# STM32MP21_CM33 register map
File version: 0.4
CPU: CM33 r0p1, little endian, MPU, FPU, vendor SysTick, 8 interrupt priority bits
Registers are 32-bit, read-write, reset 0x0 unless marked. A register's access mark holds for its fields unless they carry their own. Offsets are from the block's base; [hi:lo] are bit positions; {n}, {i} and the like mark numbered series; 'fields as' and 'values as' point back to an identical list.

## SERC — SERC register block
Base 0x44080000
Same registers: SERC_S 0x54080000
{0x0+4i} SERC_IER{i} (i=0..5) — SERC interrupt enable register {i}
  [31:0] PDRIE — Power-down or reset interrupt enable for peripheral y
    0=power-down or reset access event from peripheral y does not generate an interrupt (masked); 1=power-down or reset access event from peripheral y generates an interrupt (unmasked)
{0x40+4i} SERC_ISR{i} ro (i=0..4) — SERC interrupt status register {i}
  [31:0] PDRS — Power-down or reset interrupt status for peripheral y
    0=no power-down or reset event recorded for this peripheral; 1=a power-down or reset access event has been reported from this peripheral
0x54 SERC_ISR5 ro — SERC interrupt status register 5
  [31:0] PDRS — Power-down or reset clear flag for peripheral y
    values as SERC_ISR0.PDRS
{0x80+4i} SERC_ICR{i} wo (i=0..5) — SERC interrupt clear register {i}
  [31:0] PDRC — Power-down or reset clear flag for peripheral y
    0=PDRCy flag status is not affected; 1=PDRCy flag status is cleared in SERC_ISR{i} register
0x100 SERC_ENABLE
  [0] SERFEN — Enable the SERF framework.
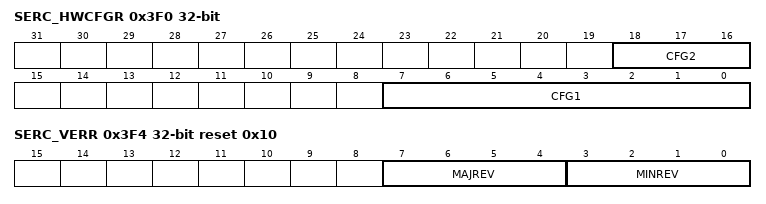
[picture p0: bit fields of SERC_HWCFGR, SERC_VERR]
0x3F0 SERC_HWCFGR ro (reset mask 0xFFF0FF00) — SERC hardware configuration register
  [18:16] CFG2 — NUM_RESYNC_FLOPS, number of resynchronization flops when receiving a bus_ilac information in the SERC clock domain.
  [7:0] CFG1 — NUM_ILAC, number of illegal accesses input pins configured for this instance of the collector.
0x3F4 SERC_VERR ro reset 0x10 — SERC version register
  [7:4] MAJREV — Major revision
  [3:0] MINREV — Minor revision
0x3F8 SERC_IPIDR ro reset 0x1001F0 — SERC identification register
  [31:0] ID — IP identification code
0x3FC SERC_SIDR ro reset 0xA3C5DD01 — SERC size identification register
  [31:0] SID — Size identification code (1 Kbyte)

## STGENC — STGENC address block description
Base 0x48080000
Same registers: STGENC_S 0x58080000
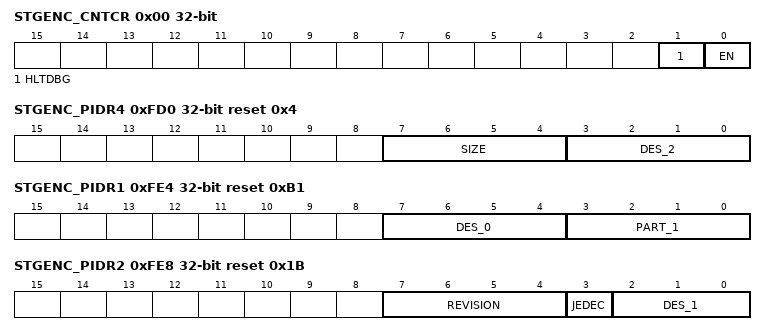
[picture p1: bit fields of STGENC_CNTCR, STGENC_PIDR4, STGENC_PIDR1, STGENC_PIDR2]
0x00 STGENC_CNTCR — STGENC control register
  [1] HLTDBG — Halt on debug
    0=Do not halt on debug; hltdbg signal into the counter has no effect; 1=Halt on debug; when hltdbg is driven high, the count value is held static
  [0] EN — Enable
    0=Counter disabled and not incrementing; 1=Counter enabled and incrementing
0x04 STGENC_CNTSR ro — STGENC status register
  [1] DBGH — Debug halted
    0=Normal operation; 1=Counter halted due to system-wide debug state
0x08 STGENC_CNTCVL — STGENC value lower register
  [31:0] CNTCVL_L_32 — Current value of the timestamp counter, lower 32 bits
0x0C STGENC_CNTCVU — STGENC value upper register
  [31:0] CNTCVU_U_32 — Current value of the timestamp counter, upper 32 bits
0x20 STGENC_CNTFID0 — STGENC base frequency register
  [31:0] FREQ — Frequency in number of ticks per second
0xFD0 STGENC_PIDR4 ro reset 0x4 — STGENC peripheral ID4 register
  [7:4] SIZE — Always 0b0000
  [3:0] DES_2 — Part of designer identification
{0xFC0+4i} STGENC_PIDR{i} ro (i=5..7) — STGENC peripheral ID{i} register
  [31:0] PIDR{i} — Peripheral ID{i}
0xFE0 STGENC_PIDR0 ro reset 0x1 — STGENC peripheral ID0 register
  [7:0] PART_0 — Bits[7:0] of the 12-bit part number of the component
0xFE4 STGENC_PIDR1 ro reset 0xB1 — STGENC peripheral ID1 register
  [7:4] DES_0 — Part of designer identification
  [3:0] PART_1 — Bits[11:8] of the 12-bit part number of the component
0xFE8 STGENC_PIDR2 ro reset 0x1B — STGENC peripheral ID2 register
  [7:4] REVISION — device revision number
  [3] JEDEC — always 1
  [2:0] DES_1 — part of designer identification
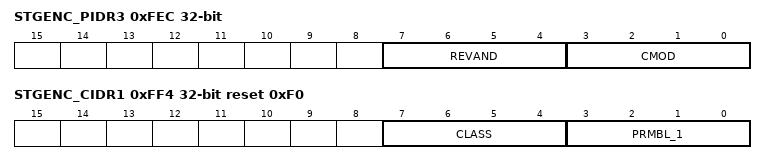
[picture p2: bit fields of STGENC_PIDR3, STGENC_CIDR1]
0xFEC STGENC_PIDR3 ro — STGENC peripheral ID3 register
  [7:4] REVAND — Customer version
  [3:0] CMOD — Customer modified
0xFF0 STGENC_CIDR0 ro reset 0xD — STGENC component ID0 register
  [7:0] PRMBL_0 — Preamble 0
0xFF4 STGENC_CIDR1 ro reset 0xF0 — STGENC component ID1 register
  [7:4] CLASS — Class of the component
  [3:0] PRMBL_1 — preamble 1
0xFF8 STGENC_CIDR2 ro reset 0x5 — STGENC component ID2 register
  [7:0] PRMBL_2 — Preamble 2
0xFFC STGENC_CIDR3 ro reset 0xB1 — STGENC component ID3 register
  [7:0] PRMBL_3 — Preamble 3

## STGENR — STGENR address block description
Base 0x48070000
Same registers: STGENR_S 0x58070000
Registers as STGENC (with STGENC read as STGENR), without STGENC_CNTCR, STGENC_CNTSR, STGENC_CNTCVL, STGENC_CNTCVU, STGENC_CNTFID0; these are added or differ:
0x00 STGENR_CNTCVL ro — STGENR value lower register
  [31:0] CNTCVL_L_32 — Current value of the timestamp counter (the lower 32 bits)
0x04 STGENR_CNTCVU ro — STGENR value upper register
  [31:0] CNTCVU_U_32 — Current value of the timestamp counter (the upper 32 bits)
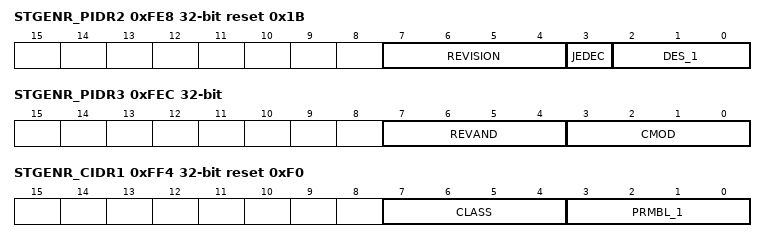
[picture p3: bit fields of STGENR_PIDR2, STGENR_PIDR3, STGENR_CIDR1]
0xFE8 STGENR_PIDR2 ro reset 0x1B — STGENR peripheral ID2 register
  [7:4] REVISION — Device revision number
  [3] JEDEC — Always 1
  [2:0] DES_1 — Part of designer identification
0xFEC STGENR_PIDR3 ro — STGENR peripheral ID3 register
  [7:4] REVAND — Errata fix identification
  [3:0] CMOD — Customer modified
0xFF4 STGENR_CIDR1 ro reset 0xF0 — STGENR component ID1 register
  [7:4] CLASS — Class of the component
  [3:0] PRMBL_1 — Preamble 1
0xFF8 STGENR_CIDR2 ro reset 0x50 — STGENR component ID2 register
  [7:0] PRMBL_2 — Preamble 2

## VREFBUF — VREFBUF address block description
Base 0x44060000
Same registers: VREFBUF_S 0x54060000
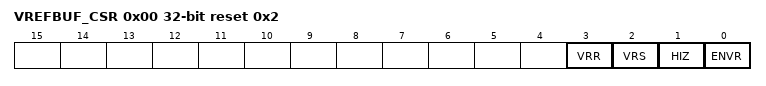
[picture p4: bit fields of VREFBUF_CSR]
0x00 VREFBUF_CSR reset 0x2 — VREFBUF control and status register
  [3] VRR ro — Voltage reference buffer ready
    0=the voltage reference buffer output is not ready; 1=the voltage reference buffer output reached the requested level
  [2] VRS — Voltage reference scale
    0=Voltage reference set to 2; 1=Voltage reference set to 2
  [1] HIZ — High impedance mode
    0=Vless thansub>REF+less than/sub> pin is internally connected to the voltage reference buffer output; 1=Vless thansub>REF+less than/sub> pin is high impedance
  [0] ENVR — Voltage reference buffer mode enable
    0=Internal voltage reference mode disable (external voltage reference mode); 1=Internal voltage reference mode (reference buffer enable or hold mode) enable
0x04 VREFBUF_CCR (reset mask 0xFFFFFF00) — VREFBUF calibration control register
  [5:0] TRIM — Trimming code

## WWDG — WWDG address block description
Base 0x44050000
Same registers: WWDG_S 0x54050000
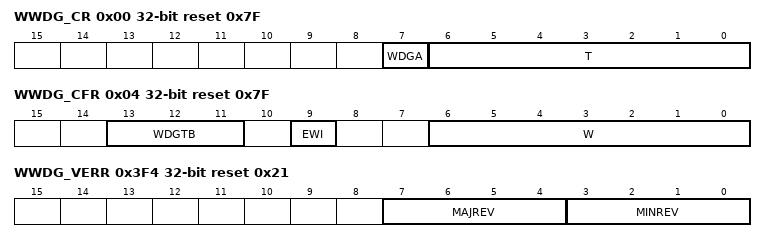
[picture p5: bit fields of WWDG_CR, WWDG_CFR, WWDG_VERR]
0x00 WWDG_CR reset 0x7F — WWDG control register
  [7] WDGA — Activation bit
    0=Watchdog disabled; 1=Watchdog enabled
  [6:0] T — 7-bit counter (MSB to LSB)
0x04 WWDG_CFR reset 0x7F — WWDG configuration register
  [13:11] WDGTB — Timer base
    0=CK counter clock (PCLK div 4096) div 1; 1=CK counter clock (PCLK div 4096) div 2; 2=CK counter clock (PCLK div 4096) div 4; 3=CK counter clock (PCLK div 4096) div 8; 4=CK counter clock (PCLK div 4096) div 16; 5=CK counter clock (PCLK div 4096) div 32; 6=CK counter clock (PCLK div 4096) div 64; 7=CK counter clock (PCLK div 4096) div 128
  [9] EWI — Early wake-up interrupt enable
  [6:0] W — 7-bit window value
0x08 WWDG_SR — WWDG status register
  [0] EWIF — Early wake-up interrupt flag
0x3F0 WWDG_HWCFGR ro reset 0x1000 — WWDG hardware configuration register
  [15:0] PREDIV — The watchdog clock is prescaled by 4096 (PREDIV[15:0]).
0x3F4 WWDG_VERR ro reset 0x21 — WWDG version register
  [7:4] MAJREV — WWDG major revision
  [3:0] MINREV — WWDG minor revision
0x3F8 WWDG_IPIDR ro reset 0x120051 — WWDG identification register
  [31:0] ID — WWDG peripheral identifier
0x3FC WWDG_SIDR ro reset 0xA3C5DD01 — WWDG size identification register
  [31:0] SID — The address decoding range is 1 Kbyte
